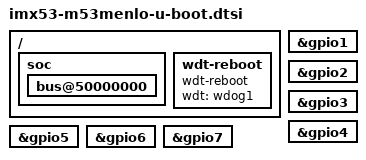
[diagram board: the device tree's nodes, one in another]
// SPDX-License-Identifier: (GPL-2.0+ OR MIT)
/*
 * Copyright (C) 2019 Marek Vasut <marex@denx.de>
 */

/ {
	soc {
		u-boot,dm-all;

		bus@50000000 {
			u-boot,dm-all;
		};
	};

	wdt-reboot {
		compatible = "wdt-reboot";
		wdt = <&wdog1>;
	};
};

&gpio1 {
	u-boot,dm-all;
};

&gpio2 {
	u-boot,dm-all;
};

&gpio3 {
	u-boot,dm-all;
};

&gpio4 {
	u-boot,dm-all;
};

&gpio5 {
	u-boot,dm-all;
};

&gpio6 {
	u-boot,dm-all;
};

&gpio7 {
	u-boot,dm-all;
};
